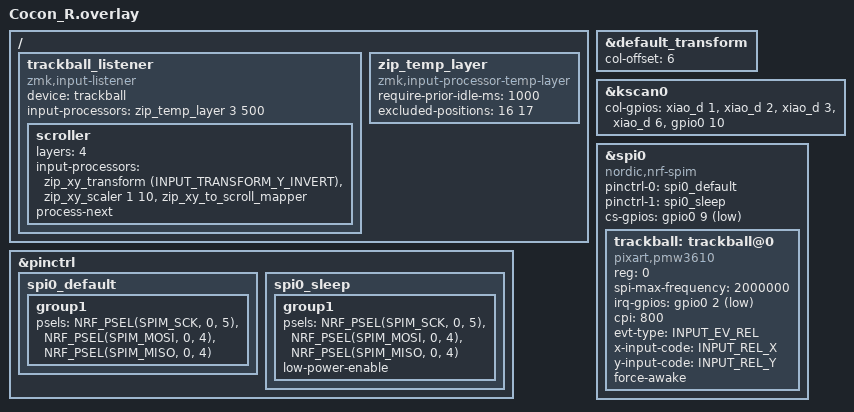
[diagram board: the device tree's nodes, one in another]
#include "Cocon.dtsi"
#include <input/processors.dtsi>
#include <dt-bindings/zmk/input_transform.h>

&default_transform {
    col-offset = <6>;
};

&kscan0 {
        col-gpios
            = <&xiao_d 1 GPIO_ACTIVE_HIGH>
            , <&xiao_d 2 GPIO_ACTIVE_HIGH>
            , <&xiao_d 3 GPIO_ACTIVE_HIGH>
            , <&xiao_d 6 GPIO_ACTIVE_HIGH>
            , <&gpio0 10 GPIO_ACTIVE_HIGH>
            ;
};

/ {
    trackball_listener {
        compatible = "zmk,input-listener";
        device = <&trackball>;

    };
};

&pinctrl {
    spi0_default: spi0_default {
        group1 {
            psels = <NRF_PSEL(SPIM_SCK, 0, 5)>,
                <NRF_PSEL(SPIM_MOSI, 0, 4)>,
                <NRF_PSEL(SPIM_MISO, 0, 4)>;
        };
    };

    spi0_sleep: spi0_sleep {
        group1 {
            psels = <NRF_PSEL(SPIM_SCK, 0, 5)>,
                <NRF_PSEL(SPIM_MOSI, 0, 4)>,
                <NRF_PSEL(SPIM_MISO, 0, 4)>;
            low-power-enable;
        };
    };
};

#include <zephyr/dt-bindings/input/input-event-codes.h>

&spi0 {
    status = "okay";
    compatible = "nordic,nrf-spim";
    pinctrl-0 = <&spi0_default>;
    pinctrl-1 = <&spi0_sleep>;
    pinctrl-names = "default", "sleep";
    cs-gpios = <&gpio0 9 GPIO_ACTIVE_LOW>;

    trackball: trackball@0 {
        status = "okay";
        compatible = "pixart,pmw3610";
        reg = <0>;
        spi-max-frequency = <2000000>;
        irq-gpios = <&gpio0 2 (GPIO_ACTIVE_LOW | GPIO_PULL_UP)>;
        cpi = <800>;
        evt-type = <INPUT_EV_REL>;
        x-input-code = <INPUT_REL_X>;
        y-input-code = <INPUT_REL_Y>;

        force-awake;
        /* keep the sensor awake while ZMK activity state is ACTIVE,
           fallback to normal downshift mode after ZMK goes into IDLE / SLEEP mode.
           thus, the sensor would be a `wakeup-source` */
    };
};

/ {
    /omit-if-no-ref/ zip_temp_layer: zip_temp_layer {
        compatible = "zmk,input-processor-temp-layer";
        #input-processor-cells = <2>;
        require-prior-idle-ms = <1000>;
        excluded-positions = <
            16 // J
            17 // K
        >;
    };

    trackball_listener {
        compatible = "zmk,input-listener";
        device = <&trackball>;
        input-processors = <&zip_temp_layer 3 500>;

        scroller {
            layers = <4>;
            input-processors = <&zip_xy_transform (INPUT_TRANSFORM_Y_INVERT)>, <&zip_xy_scaler 1 10>, <&zip_xy_to_scroll_mapper>;
            process-next;
        };
    };
};


